# tviibe2m register map
Vendor: Infineon Technologies; Series: TVIIBE2M; File version: 1.0
CPU: CM4 r0p1, little endian, MPU, FPU, VTOR, 3 interrupt priority bits
Registers are 32-bit, read-write, reset 0x0 unless marked. A register's access mark holds for its fields unless they carry their own. Offsets are from the block's base; [hi:lo] are bit positions; lines under a group give offsets from that group; {n}, {i} and the like mark numbered series.

## PERI — Peripheral interconnect
Base 0x40000000
0x200 TIMEOUT_CTL reset 0xFFFF — Timeout control
  [15:0] TIMEOUT — This field specifies a number of clock cycles (clk_slow). If an AHB-Lite bus transfer takes more than the specified number of cycles (timeout detection), the bus transfer is terminated with an AHB-Lite bus error and a fault is generated (and possibly recorded in the fault report structure(s)). '0x0000'-'0xfffe': Number of clock cycles. '0xffff': This value is the default/reset value and specifies that no timeout detection is performed: a bus transfer will never be terminated and a fault will never be generated.
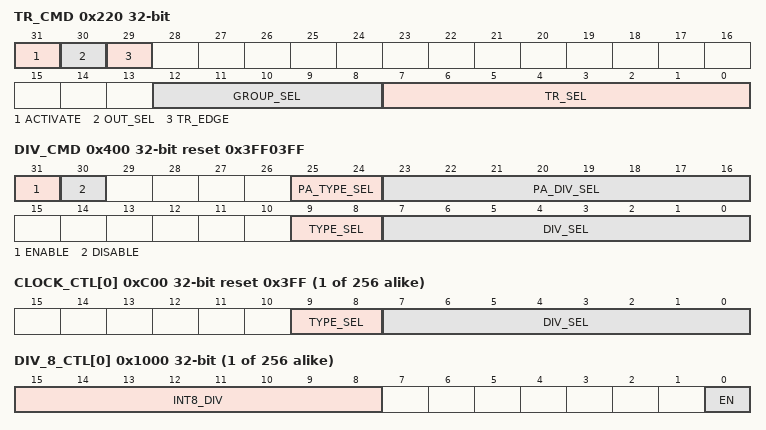
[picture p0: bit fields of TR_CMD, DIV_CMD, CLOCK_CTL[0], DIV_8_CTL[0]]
0x220 TR_CMD — Trigger command
  [31] ACTIVATE — SW sets this field to '1' to activate (set to '1') a trigger as identified by TR_SEL, TR_EDGE and OUT_SEL. HW sets this field to '0' for edge sensitive triggers AFTER the selected trigger is activated for two clk_peri cycles. Note: when ACTIVATE is '1', SW should not modify the other register fields. SW MUST NOT set ACTIVATE bit to '1' while updating the other register bits simultaneously. At first the SW MUST update the other register bits as needed, and then set ACTIVATE to '1' with a new register write.
  [30] OUT_SEL — Specifies whether trigger activation is for a specific input or output trigger of the trigger multiplexer. Activation of a specific input trigger, will result in activation of all output triggers that have the specific input trigger selected through their TR_OUT_CTL.TR_SEL field. Activation of a specific output trigger, will result in activation of the specified TR_SEL output trigger only. '0': TR_SEL selection and trigger activation is for an input trigger to the trigger multiplexer. '1': TR_SEL selection and trigger activation is for an output trigger from the trigger multiplexer. Note: this field is not used for trigger 1-to-1 groups.
  [29] TR_EDGE — Specifies if the activated trigger is treated as a level sensitive or edge sensitive trigger. '0': level sensitive. The trigger reflects TR_CMD.ACTIVATE. '1': edge sensitive trigger. The trigger is activated for two clk_peri cycles.
  [12:8] GROUP_SEL — Specifies the trigger group: '0'-'15': trigger multiplexer groups. '16'-'31': trigger 1-to-1 groups.
  [7:0] TR_SEL — Specifies the activated trigger when ACTIVATE is '1'. If the specified trigger is not present, the trigger activation has no effect.
0x400 DIV_CMD reset 0x3FF03FF — Divider command
  [31] ENABLE — Clock divider enable command (mutually exclusive with DISABLE). Typically, SW sets this field to '1' to enable a divider and HW sets this field to '0' to indicate that divider enabling has completed. When a divider is enabled, its integer and fractional (if present) counters are initialized to '0'. If a divider is to be re-enabled using different integer and fractional divider values, the SW should follow these steps: 0: Disable the divider using the DIV_CMD.DISABLE field. 1: Configure the divider's DIV_XXX_CTL register. 2: Enable the divider using the DIV_CMD_ENABLE field. The DIV_SEL and TYPE_SEL fields specify which divider is to be enabled. The enabled divider may be phase aligned to either 'clk_peri' (typical usage) or to ANY enabled divider. The PA_DIV_SEL and PA_TYPE_SEL fields specify the reference divider. The HW sets the ENABLE field to '0' when the enabling is performed and the HW set the DIV_XXX_CTL.EN field of the divider to '1' when the enabling is performed. Note that enabling with phase alignment to a low frequency divider takes time. E.g. To align to a divider that generates a clock of 'clk_peri'/n (with n being the integer divider value INT_DIV+1), up to n cycles may be required to perform alignment. Phase alignment to 'clk_peri' takes affect immediately. SW can set this field to '0' during phase alignment to abort the enabling process.
  [30] DISABLE — Clock divider disable command (mutually exclusive with ENABLE). SW sets this field to '1' and HW sets this field to '0'. The DIV_SEL and TYPE_SEL fields specify which divider is to be disabled. The HW sets the DISABLE field to '0' immediately and the HW sets the DIV_XXX_CTL.EN field of the divider to '0' immediately.
  [25:24] PA_TYPE_SEL — Specifies the divider type of the divider to which phase alignment is performed for the clock enable command: 0: 8.0 (integer) clock dividers. 1: 16.0 (integer) clock dividers. 2: 16.5 (fractional) clock dividers. 3: 24.5 (fractional) clock dividers.
  [23:16] PA_DIV_SEL — (PA_TYPE_SEL, PA_DIV_SEL) specifies the divider to which phase alignment is performed for the clock enable command. Any enabled divider can be used as reference. This allows all dividers to be aligned with each other, even when they are enabled at different times. If PA_DIV_SEL is '255' and PA_TYPE_SEL is '3', 'clk_peri' is used as reference.
  [9:8] TYPE_SEL — Specifies the divider type of the divider on which the command is performed: 0: 8.0 (integer) clock dividers. 1: 16.0 (integer) clock dividers. 2: 16.5 (fractional) clock dividers. 3: 24.5 (fractional) clock dividers.
  [7:0] DIV_SEL — (TYPE_SEL, DIV_SEL) specifies the divider on which the command (DISABLE/ENABLE) is performed. If DIV_SEL is '255' and TYPE_SEL is '3' (default/reset value), no divider is specified and no clock signal(s) are generated.
{0xC00+4i} CLOCK_CTL[{i}] (i=0..255) reset 0x3FF — Clock control
  [9:8] TYPE_SEL — Specifies divider type: 0: 8.0 (integer) clock dividers. 1: 16.0 (integer) clock dividers. 2: 16.5 (fractional) clock dividers. 3: 24.5 (fractional) clock dividers.
  [7:0] DIV_SEL — Specifies one of the dividers of the divider type specified by TYPE_SEL. If DIV_SEL is '255' and TYPE_SEL is '3' (default/reset value), no divider is specified and no clock control signal(s) are generated. When transitioning a clock between two out-of-phase dividers, spurious clock control signals may be generated for one 'clk_peri' cycle during this transition. These clock control signals may cause a single clock period that is smaller than any of the two divider periods. To prevent these spurious clock signals, the clock multiplexer can be disconnected (DIV_SEL is '255' and TYPE_SEL is '3') for a transition time that is larger than the smaller of the two divider periods.
{0x1000+4i} DIV_8_CTL[{i}] (i=0..255) — Divider control (for 8.0 divider)
  [15:8] INT8_DIV — Integer division by (1+INT8_DIV). Allows for integer divisions in the range [1, 256]. Note: this type of divider does NOT allow for a fractional division. For the generation of a divided clock, the integer division range is restricted to [2, 256]. For the generation of a 50/50 percent duty cycle digital divided clock, the integer division range is restricted to even numbers in the range [2, 256]. The generation of a 50/50 percent duty cycle analog divided clock has no restrictions. Note that this field is retained. However, the counter that is used to implement the division is not and will be initialized by HW to '0' when transitioning from DeepSleep to Active power mode.
  [0] EN ro — Divider enabled. HW sets this field to '1' as a result of an ENABLE command. HW sets this field to '0' as a result on a DISABLE command. Note that this field is retained. As a result, the divider does NOT have to be re-enabled after transitioning from DeepSleep to Active power mode.
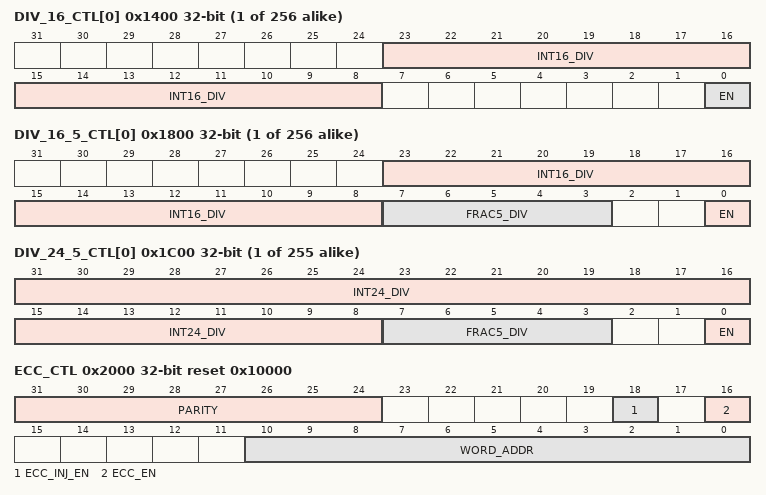
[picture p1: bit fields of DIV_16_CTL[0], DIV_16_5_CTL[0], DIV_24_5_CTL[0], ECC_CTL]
{0x1400+4i} DIV_16_CTL[{i}] (i=0..255) — Divider control (for 16.0 divider)
  [23:8] INT16_DIV — Integer division by (1+INT16_DIV). Allows for integer divisions in the range [1, 65,536]. Note: this type of divider does NOT allow for a fractional division. For the generation of a divided clock, the integer division range is restricted to [2, 65,536]. For the generation of a 50/50 percent duty cycle digital divided clock, the integer division range is restricted to even numbers in the range [2, 65,536]. The generation of a 50/50 percent duty cycle analog divided clock has no restrictions. Note that this field is retained. However, the counter that is used to implement the division is not and will be initialized by HW to '0' when transitioning from DeepSleep to Active power mode.
  [0] EN ro — Divider enabled. HW sets this field to '1' as a result of an ENABLE command. HW sets this field to '0' as a result on a DISABLE command. Note that this field is retained. As a result, the divider does NOT have to be re-enabled after transitioning from DeepSleep to Active power mode.
{0x1800+4i} DIV_16_5_CTL[{i}] (i=0..255) — Divider control (for 16.5 divider)
  [23:8] INT16_DIV — Integer division by (1+INT16_DIV). Allows for integer divisions in the range [1, 65,536]. Note: combined with fractional division, this divider type allows for a division in the range [1, 65,536 31/32] in 1/32 increments. For the generation of a divided clock, the division range is restricted to [2, 65,536 31/32]. For the generation of a 50/50 percent duty cycle divided clock, the division range is restricted to [2, 65,536]. Note that this field is retained. However, the counter that is used to implement the division is not and will be initialized by HW to '0' when transitioning from DeepSleep to Active power mode.
  [7:3] FRAC5_DIV — Fractional division by (FRAC5_DIV/32). Allows for fractional divisions in the range [0, 31/32]. Note that fractional division results in clock jitter as some clock periods may be 1 'clk_peri' cycle longer than other clock periods. Note that this field is retained. However, the counter that is used to implement the division is not and will be initialized by HW to '0' when transitioning from DeepSleep to Active power mode.
  [0] EN ro — Divider enabled. HW sets this field to '1' as a result of an ENABLE command. HW sets this field to '0' as a result on a DISABLE command. Note that this field is retained. As a result, the divider does NOT have to be re-enabled after transitioning from DeepSleep to Active power mode.
{0x1C00+4i} DIV_24_5_CTL[{i}] (i=0..254) — Divider control (for 24.5 divider)
  [31:8] INT24_DIV — Integer division by (1+INT24_DIV). Allows for integer divisions in the range [1, 16,777,216]. Note: combined with fractional division, this divider type allows for a division in the range [1, 16,777,216 31/32] in 1/32 increments. For the generation of a divided clock, the integer division range is restricted to [2, 16,777,216 31/32]. For the generation of a 50/50 percent duty cycle divided clock, the division range is restricted to [2, 16,777,216]. Note that this field is retained. However, the counter that is used to implement the division is not and will be initialized by HW to '0' when transitioning from DeepSleep to Active power mode.
  [7:3] FRAC5_DIV — Fractional division by (FRAC5_DIV/32). Allows for fractional divisions in the range [0, 31/32]. Note that fractional division results in clock jitter as some clock periods may be 1 'clk_peri' cycle longer than other clock periods. Note that this field is retained. However, the counter that is used to implement the division is not and will be initialized by HW to '0' when transitioning from DeepSleep to Active power mode.
  [0] EN ro — Divider enabled. HW sets this field to '1' as a result of an ENABLE command. HW sets this field to '0' as a result on a DISABLE command. Note that this field is retained. As a result, the divider does NOT have to be re-enabled after transitioning from DeepSleep to Active power mode.
0x2000 ECC_CTL reset 0x10000 — ECC control
  [31:24] PARITY — ECC parity to use for ECC error injection at address WORD_ADDR.
  [18] ECC_INJ_EN — Enable error injection for PERI protection structure SRAM. When '1', the parity (PARITY) is used when a write is done to the WORD_ADDR word address of the SRAM.
  [16] ECC_EN — Enable ECC checking: '0': Disabled. '1': Enabled.
  [10:0] WORD_ADDR — Specifies the word address where the parity is injected. - On a 32-bit write access to this SRAM address and when ECC_INJ_EN bit is '1', the parity (PARITY) is injected.
{0x4000+0x20*i} GR[{i}] (i=0..9) group — Peripheral group structure
  0x00 CLOCK_CTL — Clock control
    [15:8] INT8_DIV — Specifies a group clock divider (from the peripheral clock 'clk_peri' to the group clock 'clk_group[3/4/5/...15]'). Integer division by (1+INT8_DIV). Allows for integer divisions in the range [1, 256]. Note that this field is retained. However, the counter that is used to implement the division is not and will be initialized by HW to '0' when transitioning from DeepSleep to Active power mode.
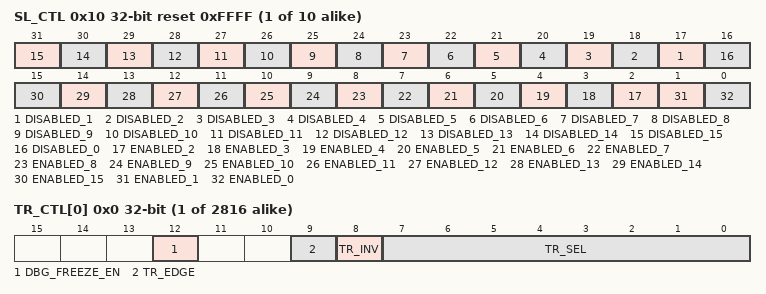
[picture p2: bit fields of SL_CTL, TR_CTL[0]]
  0x10 SL_CTL reset 0xFFFF — Slave control
    [n+16] DISABLED_{n} (n=1..15)
    [16] DISABLED_0 — Peripheral group, slave 0 permanent disable. Setting this bit to 1 has the same effect as setting ENABLED_0 to 0. However, once set to 1, this bit cannot be changed back to 0 anymore.
    [n] ENABLED_{n} (n=2..15)
    [1] ENABLED_1 — Peripheral group, slave 1 enable. If the slave is disabled, its clock is gated off (constant '0') and its resets are activated. Note: For peripheral group 0 (the peripheral interconnect, master interface MMIO registers), this field is a constant '1' (SW: R): the slave can NOT be disabled.
    [0] ENABLED_0 — Peripheral group, slave 0 enable. If the slave is disabled, its clock is gated off (constant '0') and its resets are activated. Note: For peripheral group 0 (the peripheral interconnect MMIO registers), this field is a constant '1' (SW: R): the slave can NOT be disabled.
{0x8000+0x400*i} TR_GR[{i}] (i=0..10) group — Trigger group
  {0x0+4j} TR_CTL[{j}] (j=0..255) — Trigger control register
    [12] DBG_FREEZE_EN — Specifies if the output trigger is blocked in debug mode. When set high tr_dbg_freeze will block the output trigger generation.
    [9] TR_EDGE — Specifies if the (inverted) output trigger is treated as a level sensitive or edge sensitive trigger. '0': level sensitive. '1': edge sensitive trigger. The (inverted) output trigger duration needs to be at least 2 cycles on the consumer clock. the(inverted) output trigger is synchronized to the consumer clock and a two cycle pulse is generated on the consumer clock.
    [8] TR_INV — Specifies if the output trigger is inverted.
    [7:0] TR_SEL — Specifies input trigger. This field is typically set during the setup of a chip use case scenario. Changing this field while activated triggers are present on the input triggers may result in unpredictable behavior. Note that input trigger 0 (default value) is typically connected to a constant signal level of '0', and as a result will not cause HW activation of the output trigger.
{0xC000+0x400*i} TR_1TO1_GR[{i}] (i=0..10) group — Trigger 1-to-1 group
  {0x0+4j} TR_CTL[{j}] (j=0..255) — Trigger control register
    [12] DBG_FREEZE_EN — Specifies if the output trigger is blocked in debug mode. When set high tr_dbg_freeze will block the output trigger generation.
    [9] TR_EDGE — Specifies if the (inverted) output trigger is treated as a level sensitive or edge sensitive trigger. '0': level sensitive. '1': edge sensitive trigger. The (inverted) output trigger duration needs to be at least 2 cycles on the consumer clock. the(inverted) output trigger is synchronized to the consumer clock and a two cycle pulse is generated on the consumer clock.
    [8] TR_INV — Specifies if the output trigger is inverted.
    [0] TR_SEL — Specifies input trigger: '0'': constant signal level '0'. '1': input trigger.

## Notices in the file
(c) (2016-2026), Infineon Technologies AG
or an affiliate of Infineon Technologies AG.
SPDX-License-Identifier: Apache-2.0
Licensed under the Apache License, Version 2.0 (the "License");
you may not use this file except in compliance with the License.
You may obtain a copy of the License at
http://www.apache.org/licenses/LICENSE-2.0
Unless required by applicable law or agreed to in writing, software
distributed under the License is distributed on an "AS IS" BASIS,
WITHOUT WARRANTIES OR CONDITIONS OF ANY KIND, either express or implied.
See the License for the specific language governing permissions and
limitations under the License.
